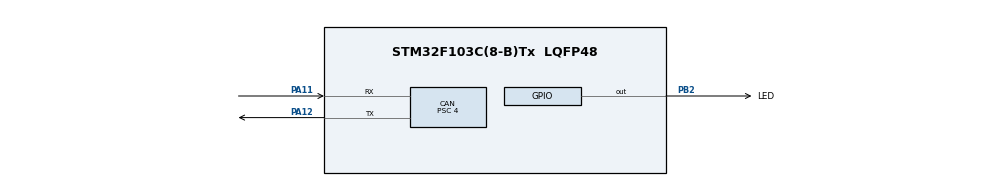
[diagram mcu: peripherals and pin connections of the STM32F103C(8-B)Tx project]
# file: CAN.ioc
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CAN.BS1=CAN_BS1_13TQ
CAN.BS2=CAN_BS2_2TQ
CAN.CalculateBaudRate=125000
CAN.CalculateTimeBit=8000
CAN.CalculateTimeQuantum=500.0
CAN.Mode=CAN_MODE_LOOPBACK
CAN.Prescaler=4
Mcu.Family=STM32F1
Mcu.Name=STM32F103C(8-B)Tx
Mcu.Package=LQFP48
NVIC.PriorityGroup=NVIC_PRIORITYGROUP_4
PA11.Mode=CAN_Activate
PA11.Signal=CAN_RX
PA12.Mode=CAN_Activate
PA12.Signal=CAN_TX
PA13.Mode=Serial_Wire
PA13.Signal=SYS_JTMS-SWDIO
PA14.Mode=Serial_Wire
PA14.Signal=SYS_JTCK-SWCLK
PB2.GPIO_Label=LED
PB2.Signal=GPIO_Output
PD0-OSC_IN.Mode=HSE-External-Oscillator
PD0-OSC_IN.Signal=RCC_OSC_IN
PD1-OSC_OUT.Mode=HSE-External-Oscillator
PD1-OSC_OUT.Signal=RCC_OSC_OUT
ProjectManager.HeapSize=0x200
ProjectManager.StackSize=0x400
ProjectManager.TargetToolchain=STM32CubeIDE
RCC.APB1Freq_Value=8000000
RCC.APB2Freq_Value=8000000
board=custom

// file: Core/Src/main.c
/* USER CODE BEGIN Header */
/**
  ******************************************************************************
  * @file           : main.c
  * @brief          : Main program body
  ******************************************************************************
  * @attention
  *
  * Copyright (c) 2026 STMicroelectronics.
  * All rights reserved.
  *
  * This software is licensed under terms that can be found in the LICENSE file
  * in the root directory of this software component.
  * If no LICENSE file comes with this software, it is provided AS-IS.
  *
  ******************************************************************************
  */
/* USER CODE END Header */
#include "main.h"

CAN_HandleTypeDef hcan;

/* USER CODE BEGIN PV */
CAN_TxHeaderTypeDef TxHeader;
 uint8_t TxData[8];
 uint32_t TxMailbox;
/* USER CODE END PV */

void SystemClock_Config(void);
static void MX_GPIO_Init(void);
static void MX_CAN_Init(void);

int main(void)
{

  /* MCU Configuration--------------------------------------------------------*/

  /* Reset of all peripherals, Initializes the Flash interface and the Systick. */
  HAL_Init();

  /* Configure the system clock */
  SystemClock_Config();

  /* Initialize all configured peripherals */
  MX_GPIO_Init();
  MX_CAN_Init();
  /* USER CODE BEGIN 2 */
  TxHeader.IDE = CAN_ID_STD;
  TxHeader.StdId = 0x123;
  TxHeader.ExtId = 0;
  TxHeader.RTR = CAN_RTR_DATA;
  TxHeader.DLC = 8;
  TxHeader.TransmitGlobalTime = DISABLE;

  for (int i = 0; i < 8; i++) {
        TxData[i] = i + 1;
    }
  if (HAL_CAN_Start(&hcan) != HAL_OK) {
        Error_Handler();
    }
  /* USER CODE END 2 */

  /* Infinite loop */
  while (1)
  {
	  if (HAL_CAN_GetTxMailboxesFreeLevel(&hcan) > 0) {
	            // Отправляем сообщение
	            if (HAL_CAN_AddTxMessage(&hcan, &TxHeader, TxData, &TxMailbox) == HAL_OK) {
	                HAL_GPIO_TogglePin(LED_GPIO_Port, LED_Pin); // Успех – одно быстрое мигание
	            } else {
	               // BlinkLED(2, 200);  // Ошибка – два медленных мигания
	            }
	        }
	        HAL_Delay(1000); // Пауза 1 секунда
  }
}

void SystemClock_Config(void)
{
  RCC_OscInitTypeDef RCC_OscInitStruct = {0};
  RCC_ClkInitTypeDef RCC_ClkInitStruct = {0};

  /** Initializes the RCC Oscillators according to the specified parameters
  * in the RCC_OscInitTypeDef structure.
  */
  RCC_OscInitStruct.OscillatorType = RCC_OSCILLATORTYPE_HSI;
  RCC_OscInitStruct.HSIState = RCC_HSI_ON;
  RCC_OscInitStruct.HSICalibrationValue = RCC_HSICALIBRATION_DEFAULT;
  RCC_OscInitStruct.PLL.PLLState = RCC_PLL_NONE;
  if (HAL_RCC_OscConfig(&RCC_OscInitStruct) != HAL_OK)
  {
    Error_Handler();
  }

  /** Initializes the CPU, AHB and APB buses clocks
  */
  RCC_ClkInitStruct.ClockType = RCC_CLOCKTYPE_HCLK|RCC_CLOCKTYPE_SYSCLK
                              |RCC_CLOCKTYPE_PCLK1|RCC_CLOCKTYPE_PCLK2;
  RCC_ClkInitStruct.SYSCLKSource = RCC_SYSCLKSOURCE_HSI;
  RCC_ClkInitStruct.AHBCLKDivider = RCC_SYSCLK_DIV1;
  RCC_ClkInitStruct.APB1CLKDivider = RCC_HCLK_DIV1;
  RCC_ClkInitStruct.APB2CLKDivider = RCC_HCLK_DIV1;

  if (HAL_RCC_ClockConfig(&RCC_ClkInitStruct, FLASH_LATENCY_0) != HAL_OK)
  {
    Error_Handler();
  }
}

static void MX_CAN_Init(void)
{

  hcan.Instance = CAN1;
  hcan.Init.Prescaler = 4;
  hcan.Init.Mode = CAN_MODE_LOOPBACK;
  hcan.Init.SyncJumpWidth = CAN_SJW_1TQ;
  hcan.Init.TimeSeg1 = CAN_BS1_13TQ;
  hcan.Init.TimeSeg2 = CAN_BS2_2TQ;
  hcan.Init.TimeTriggeredMode = DISABLE;
  hcan.Init.AutoBusOff = DISABLE;
  hcan.Init.AutoWakeUp = DISABLE;
  hcan.Init.AutoRetransmission = DISABLE;
  hcan.Init.ReceiveFifoLocked = DISABLE;
  hcan.Init.TransmitFifoPriority = DISABLE;
  if (HAL_CAN_Init(&hcan) != HAL_OK)
  {
    Error_Handler();
  }

}

static void MX_GPIO_Init(void)
{
  GPIO_InitTypeDef GPIO_InitStruct = {0};

  /* GPIO Ports Clock Enable */
  __HAL_RCC_GPIOD_CLK_ENABLE();
  __HAL_RCC_GPIOB_CLK_ENABLE();
  __HAL_RCC_GPIOA_CLK_ENABLE();

  /*Configure GPIO pin Output Level */
  HAL_GPIO_WritePin(LED_GPIO_Port, LED_Pin, GPIO_PIN_RESET);

  /*Configure GPIO pin : LED_Pin */
  GPIO_InitStruct.Pin = LED_Pin;
  GPIO_InitStruct.Mode = GPIO_MODE_OUTPUT_PP;
  GPIO_InitStruct.Pull = GPIO_NOPULL;
  GPIO_InitStruct.Speed = GPIO_SPEED_FREQ_LOW;
  HAL_GPIO_Init(LED_GPIO_Port, &GPIO_InitStruct);

}

void Error_Handler(void)
{
  __disable_irq();
  while (1)
  {
  }
}
